# nrf9120_mlm1_modem register map
Vendor: Nordic Semiconductor; Series: nrf91; File version: 1
CPU: CM4 r0p1, little endian, MPU, no FPU, 3 interrupt priority bits
Registers are 32-bit, read-write, reset 0x0 unless marked. A register's access mark holds for its fields unless they carry their own. Offsets are from the block's base; [hi:lo] are bit positions; lines under a group give offsets from that group; {n}, {i} and the like mark numbered series.

## VMC — Volatile Memory controller
Base 0x40061000
{0x600+0x10*i} RAM[{i}] (i=0..3) group — Unspecified
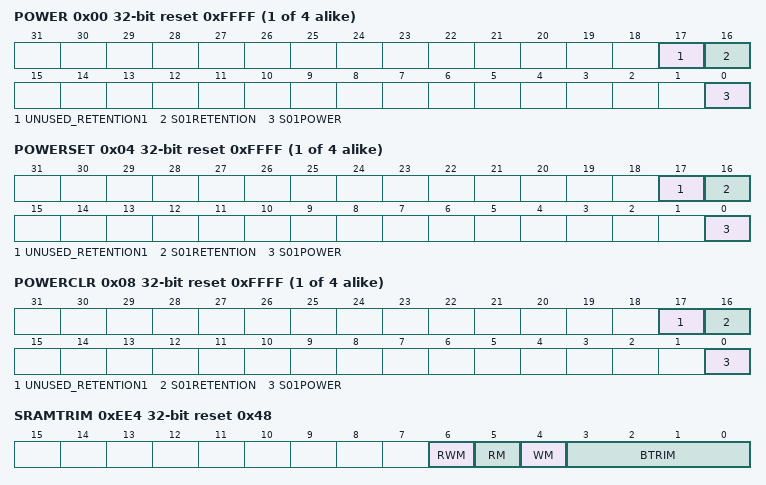
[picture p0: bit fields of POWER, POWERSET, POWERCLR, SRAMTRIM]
  0x00 POWER reset 0xFFFF — Description cluster: RAMn power control register
    [17] UNUSED_RETENTION1 — Unused retention control bit
    [16] S01RETENTION — Unused retention control bit
    [0] S01POWER — Unused power control bit
  0x04 POWERSET wo reset 0xFFFF — Description cluster: RAMn power control set register
    [17] UNUSED_RETENTION1 — Unused retention set control bit
    [16] S01RETENTION — Unused power control bit
    [0] S01POWER — Unused power control bit
  0x08 POWERCLR wo reset 0xFFFF — Description cluster: RAMn power control clear register
    [17] UNUSED_RETENTION1 — Unused retention clear control bit
    [16] S01RETENTION — Unused power control bit
    [0] S01POWER — Unused power control bit
0x700 RAMA group — Unspecified
  0x00 POWER reset 0xFFFF — RAM B{n} power control register
    [n+17] UNUSED_RETENTION{n} (n=0..14) — Unused retention bit {n}
    [16] S015RETENTION — Keep retention on RAM section S0-S15 of RAM B{n} when RAM section is switched off
      0=Off; 1=On
    [0] S015POWER — Keep RAM sections S0-S15 of RAM B{n} on or off in System ON mode
      0=Off; 1=On
  0x04 POWERSET wo reset 0xFFFF — RAM B{n} power control set register
    [n+17] UNUSED_RETENTION{n} (n=0..14) — Unused retention set bit {n}
    [16] S015RETENTION — Keep retention on RAM section S0-S15 of RAM B{n} when RAM section is switched off
      1=On
    [0] S015POWER — Keep RAM section S0-S15 of RAM B{n} on or off in System ON mode
      1=On
  0x08 POWERCLR wo reset 0xFFFF — RAM B{n} power control clear register
    [n+17] UNUSED_RETENTION{n} (n=0..14) — Unused retention set bit {n}
    [16] S015RETENTION — Keep retention on RAM section S0-S15 of RAM B{n} when RAM section is switched off
      1=Off
    [0] S015POWER — Keep RAM section S0-S15 of RAM B{n} on or off in System ON mode
      1=Off
{0x710+0x10*i} RAMB[{i}] (i=0..1) group — Unspecified
  0x00 POWER reset 0xFFFF — Description cluster: RAM Bn power control register
    [n+17] UNUSED_RETENTION{n} (n=0..10) — Unused retention bit {n}
    [16] S015RETENTION — Keep retention on RAM section S0-S15 of RAM Bn when RAM section is switched off
      0=Off; 1=On
    [0] S015POWER — Keep RAM sections S0-S15 of RAM Bn on or off in System ON mode
      0=Off; 1=On
  0x04 POWERSET wo reset 0xFFFF — Description cluster: RAM Bn power control set register
    [n+17] UNUSED_RETENTION{n} (n=0..10) — Unused retention set bit {n}
    [16] S015RETENTION — Keep retention on RAM section S0-S15 of RAM Bn when RAM section is switched off
      1=On
    [0] S015POWER — Keep RAM section S0-S15 of RAM Bn on or off in System ON mode
      1=On
  0x08 POWERCLR wo reset 0xFFFF — Description cluster: RAM Bn power control clear register
    [n+17] UNUSED_RETENTION{n} (n=0..10) — Unused retention set bit {n}
    [16] S015RETENTION — Keep retention on RAM section S0-S15 of RAM Bn when RAM section is switched off
      1=Off
    [0] S015POWER — Keep RAM section S0-S15 of RAM Bn on or off in System ON mode
      1=Off
{0x800+0x10*i} RAMC[{i}] (i=0..1) group — Unspecified
  0x00 POWER reset 0xFFFF — Description cluster: RAM Cn power control register
    [17] UNUSED_RETENTION1 — Unused retention bit
    [16] S01RETENTION — Keep retention on RAM sections S0 and S1 of RAM Cn when RAM section is switched off
      0=Off; 1=On
    [0] S01POWER — Keep RAM sections S0 and S1 of RAM Cn on or off in System ON mode
      0=Off; 1=On
  0x04 POWERSET wo reset 0xFFFF — Description cluster: RAM Cn power control set register
    [17] UNUSED_RETENTION1 — Unused retention set bit
    [16] S01RETENTION — Keep retention on sections S0 and S1 of RAM of RAM Cn when RAM section is switched off
      1=On
    [0] S01POWER — Keep RAM sections S0 and S1 of RAM Cn on or off in System ON mode
      1=On
  0x08 POWERCLR wo reset 0xFFFF — Description cluster: RAM Cn power control clear register
    [17] UNUSED_RETENTION1 — Unused retention clear bit
    [16] S01RETENTION — Keep retention on RAM sections S0 and S1 of RAM Cn when RAM section is switched off
      1=Off
    [0] S01POWER — Keep RAM sections S0 and S1 of RAM Cn on or off in System ON mode
      1=Off
0x900 RAMD group — Unspecified
  0x00 POWER reset 0xFFFF — RAM D{n} power control register
    [17] UNUSED_RETENTION1 — Unused retention bit
    [16] S01RETENTION — Keep retention on RAM sections S0 and S1 of RAM D{n} when RAM section is switched off
      0=Off; 1=On
    [0] S01POWER — Keep RAM sections S0 and S1 of RAM D{n} on or off in System ON mode
      0=Off; 1=On
  0x04 POWERSET wo reset 0xFFFF — RAM D{n} power control set register
    [17] UNUSED_RETENTION1 — Unused retention set bit
    [16] S01RETENTION — Keep retention on sections S0 and S1 of RAM of RAM D{n} when RAM section is switched off
      1=On
    [0] S01POWER — Keep RAM sections S0 and S1 of RAM D{n} on or off in System ON mode
      1=On
  0x08 POWERCLR wo reset 0xFFFF — RAM D{n} power control clear register
    [17] UNUSED_RETENTION1 — Unused retention clear bit
    [16] S01RETENTION — Keep retention on RAM sections S0 and S1 of RAM D{n} when RAM section is switched off
      1=Off
    [0] S01POWER — Keep RAM sections S0 and S1 of RAM D{n} on or off in System ON mode
      1=Off
0xEE4 SRAMTRIM reset 0x48 — Backdoor trim values for SRAM
  [6] RWM — Read/Write Margin Adjustment
    0=Disabled; 1=Enabled
  [5] RM — Read Margin Adjustment
    0=Disabled; 1=Enabled
  [4] WM — Write Margin Adjustment
    0=Disabled; 1=Enabled
  [3:0] BTRIM — Source Bias Trim Adjustment for retention
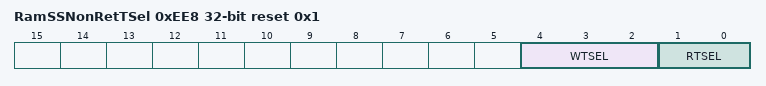
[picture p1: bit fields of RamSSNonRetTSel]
0xEE8 RamSSNonRetTSel reset 0x1 — Timing control values for TSMC RAMs
  [4:2] WTSEL — Write cycle timing selection
  [1:0] RTSEL — Read cycle timing selection
